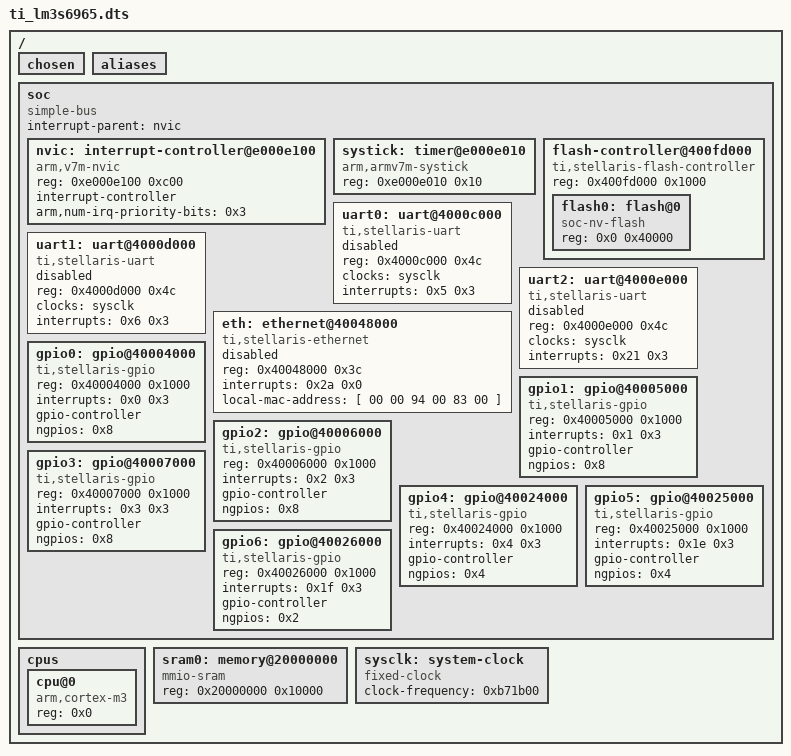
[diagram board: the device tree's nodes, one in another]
/dts-v1/;

/ {
	#address-cells = < 0x1 >;
	#size-cells = < 0x1 >;
	chosen {
	};
	aliases {
	};
	soc {
		#address-cells = < 0x1 >;
		#size-cells = < 0x1 >;
		compatible = "simple-bus";
		interrupt-parent = < &nvic >;
		ranges;
		nvic: interrupt-controller@e000e100 {
			#address-cells = < 0x1 >;
			compatible = "arm,v7m-nvic";
			reg = < 0xe000e100 0xc00 >;
			interrupt-controller;
			#interrupt-cells = < 0x2 >;
			arm,num-irq-priority-bits = < 0x3 >;
			phandle = < 0x1 >;
		};
		systick: timer@e000e010 {
			compatible = "arm,armv7m-systick";
			reg = < 0xe000e010 0x10 >;
		};
		flash-controller@400fd000 {
			compatible = "ti,stellaris-flash-controller";
			reg = < 0x400fd000 0x1000 >;
			#address-cells = < 0x1 >;
			#size-cells = < 0x1 >;
			flash0: flash@0 {
				compatible = "soc-nv-flash";
				reg = < 0x0 0x40000 >;
			};
		};
		uart0: uart@4000c000 {
			compatible = "ti,stellaris-uart";
			reg = < 0x4000c000 0x4c >;
			clocks = < &sysclk >;
			interrupts = < 0x5 0x3 >;
			status = "disabled";
		};
		uart1: uart@4000d000 {
			compatible = "ti,stellaris-uart";
			reg = < 0x4000d000 0x4c >;
			clocks = < &sysclk >;
			interrupts = < 0x6 0x3 >;
			status = "disabled";
		};
		uart2: uart@4000e000 {
			compatible = "ti,stellaris-uart";
			reg = < 0x4000e000 0x4c >;
			clocks = < &sysclk >;
			interrupts = < 0x21 0x3 >;
			status = "disabled";
		};
		eth: ethernet@40048000 {
			compatible = "ti,stellaris-ethernet";
			reg = < 0x40048000 0x3c >;
			interrupts = < 0x2a 0x0 >;
			status = "disabled";
			local-mac-address = [ 00 00 94 00 83 00 ];
		};
		gpio0: gpio@40004000 {
			compatible = "ti,stellaris-gpio";
			reg = < 0x40004000 0x1000 >;
			interrupts = < 0x0 0x3 >;
			gpio-controller;
			#gpio-cells = < 0x2 >;
			ngpios = < 0x8 >;
		};
		gpio1: gpio@40005000 {
			compatible = "ti,stellaris-gpio";
			reg = < 0x40005000 0x1000 >;
			interrupts = < 0x1 0x3 >;
			gpio-controller;
			#gpio-cells = < 0x2 >;
			ngpios = < 0x8 >;
		};
		gpio2: gpio@40006000 {
			compatible = "ti,stellaris-gpio";
			reg = < 0x40006000 0x1000 >;
			interrupts = < 0x2 0x3 >;
			gpio-controller;
			#gpio-cells = < 0x2 >;
			ngpios = < 0x8 >;
		};
		gpio3: gpio@40007000 {
			compatible = "ti,stellaris-gpio";
			reg = < 0x40007000 0x1000 >;
			interrupts = < 0x3 0x3 >;
			gpio-controller;
			#gpio-cells = < 0x2 >;
			ngpios = < 0x8 >;
		};
		gpio4: gpio@40024000 {
			compatible = "ti,stellaris-gpio";
			reg = < 0x40024000 0x1000 >;
			interrupts = < 0x4 0x3 >;
			gpio-controller;
			#gpio-cells = < 0x2 >;
			ngpios = < 0x4 >;
		};
		gpio5: gpio@40025000 {
			compatible = "ti,stellaris-gpio";
			reg = < 0x40025000 0x1000 >;
			interrupts = < 0x1e 0x3 >;
			gpio-controller;
			#gpio-cells = < 0x2 >;
			ngpios = < 0x4 >;
		};
		gpio6: gpio@40026000 {
			compatible = "ti,stellaris-gpio";
			reg = < 0x40026000 0x1000 >;
			interrupts = < 0x1f 0x3 >;
			gpio-controller;
			#gpio-cells = < 0x2 >;
			ngpios = < 0x2 >;
		};
	};
	cpus {
		#address-cells = < 0x1 >;
		#size-cells = < 0x0 >;
		cpu@0 {
			device_type = "cpu";
			compatible = "arm,cortex-m3";
			reg = < 0x0 >;
		};
	};
	sram0: memory@20000000 {
		compatible = "mmio-sram";
		reg = < 0x20000000 0x10000 >;
	};
	sysclk: system-clock {
		compatible = "fixed-clock";
		clock-frequency = < 0xb71b00 >;
		#clock-cells = < 0x0 >;
		phandle = < 0x2 >;
	};
};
